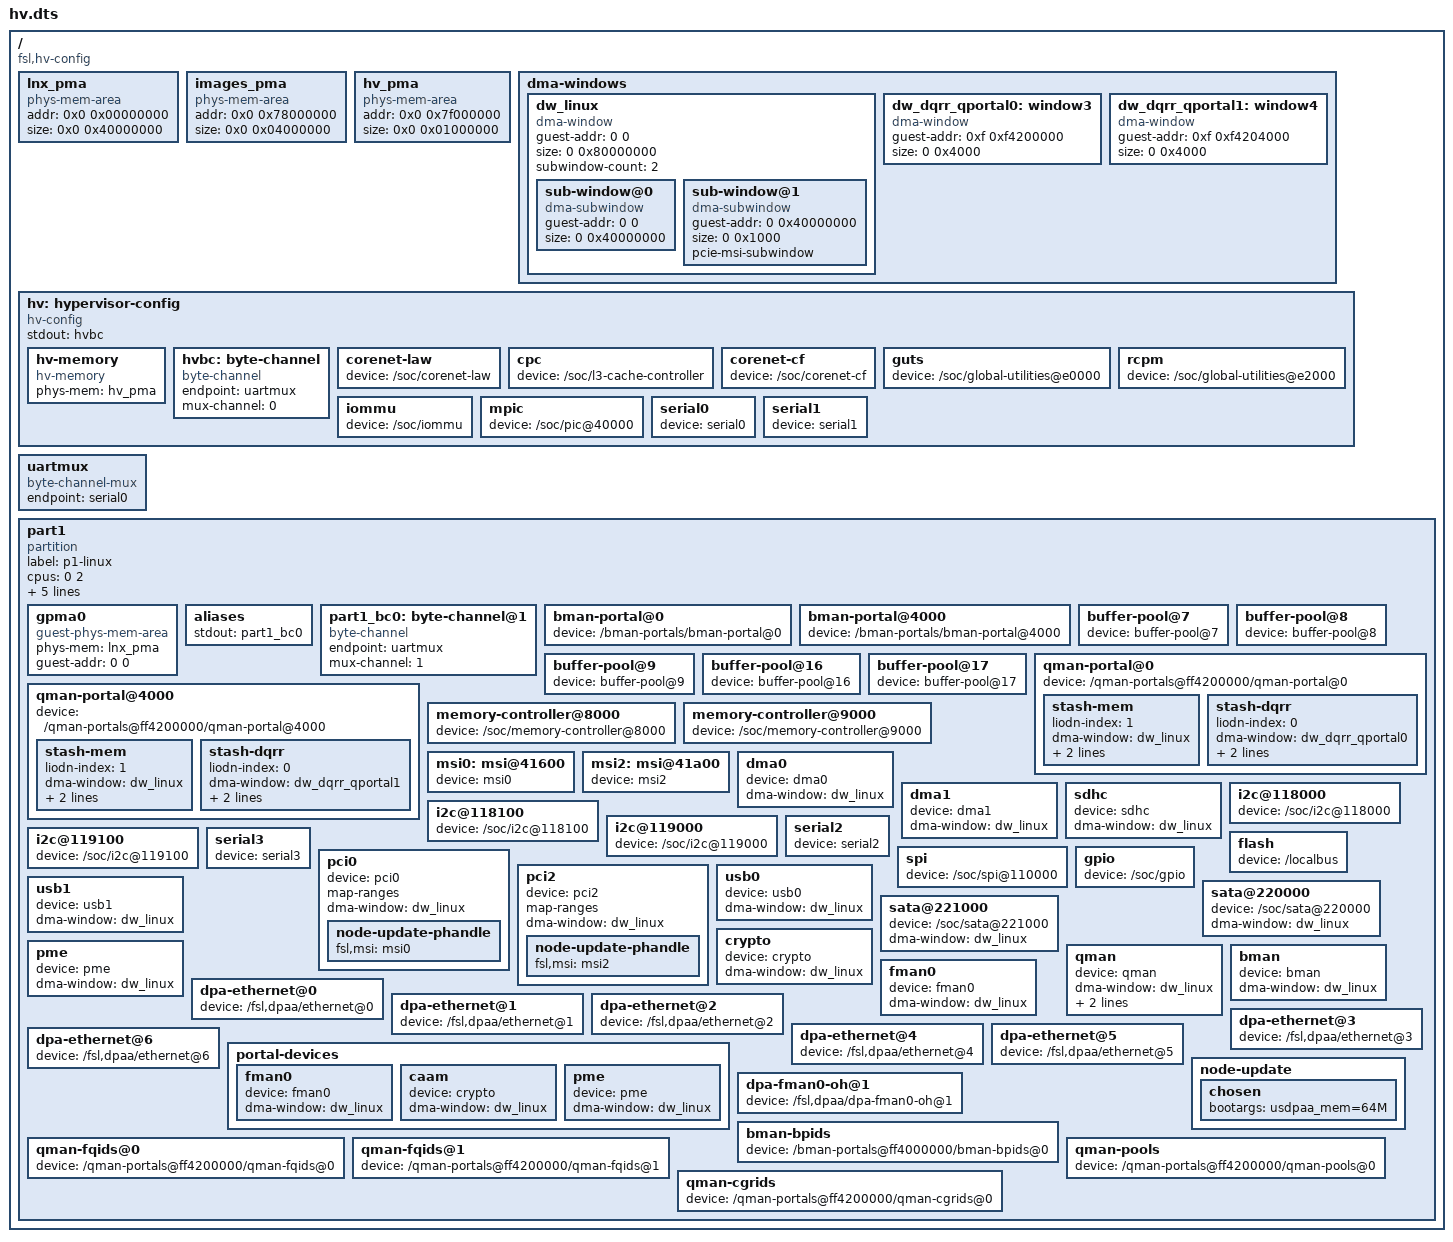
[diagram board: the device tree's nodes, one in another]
/* Hypervisor Configuration tree containing all hypervisor configuration
 * parameters and partition definition information.
 * (Note -- Please refer to Hypervisor SW Reference Manual
 * (Chapter 5 Configuration) for further details)
 *
 * Copyright 2011 Freescale Semiconductor, Inc.
 */

/dts-v1/;

/ {	// root node

	// The root node of the configuration device tree must contain a
	// compatible property that identifies the device tree as a hypervisor

	compatible = "fsl,hv-config";

	// =====================================================
	// Physical Memory Areas
	// =====================================================
	lnx_pma: lnx_pma {
		compatible = "phys-mem-area";
		addr = <0x0 0x00000000>;	// Linux
		size = <0x0 0x40000000>;	// 1GB
	};

	images_pma: images_pma {
		compatible = "phys-mem-area";
		addr = <0x0 0x78000000>;	// Used for boot-from-RAM
 		size = <0x0 0x04000000>;	// 64MB
 	};

	hv_pma: hv_pma {
		compatible = "phys-mem-area";
		addr = <0x0 0x7f000000>;	// Hypervisor
		size = <0x0 0x01000000>;	// 16MB
	};

	// =====================================================
	// DMA Windows
	// =====================================================
	dma-windows {
		// DMA window for part1_linux
		dw_linux: dw_linux {
			compatible = "dma-window";
			guest-addr = <0 0>;
			size = <0 0x80000000>; //2GB
			subwindow-count = <2>;
			sub-window@0 {
				compatible = "dma-subwindow";
				guest-addr = <0 0>;
				size = <0 0x40000000>; // 1GB
			};
			sub-window@1 {		// MSI sub-window
				compatible = "dma-subwindow";
				guest-addr = <0 0x40000000>;
				size = <0 0x1000>; // 4KB
				pcie-msi-subwindow;
			};

		};

		// DMA window for stash_dqrr for qman-portal0
		dw_dqrr_qportal0: window3 {
			compatible = "dma-window";
			guest-addr = <0xf 0xf4200000>;
			size = <0 0x4000>;
		};

		// DMA window for stash_dqrr for qman-portal1
		dw_dqrr_qportal1: window4 {
			compatible = "dma-window";
			guest-addr = <0xf 0xf4204000>;
			size = <0 0x4000>;
		};
	};

	// =====================================================
	// Hypervisor Config
	// Hypervisor is also configured via the Hypervisor
	// configuration tree. A special node and subtree defines
	// set of global configuration parameters and a number of
	// device nodes assigning I/O devices to the hypervisor
	// =====================================================
	hv: hypervisor-config {
		compatible = "hv-config";

		// phandle to byte-channel used for hypervisor's console
		stdout = <&hvbc>;

		hv-memory {
			compatible = "hv-memory";
			phys-mem = <&hv_pma>;
		};

		hvbc: byte-channel {
			compatible = "byte-channel";
			endpoint = <&uartmux>;
			mux-channel = <0>;
		};

		// Device nodes given below are the physical I/O
		// devices assigned to hypervisor
		corenet-law {
			device = "/soc/corenet-law";
		};

		cpc {
			device = "/soc/l3-cache-controller";
		};

		corenet-cf {
			device = "/soc/corenet-cf";
		};

		guts {
			device = "/soc/global-utilities@e0000";
		};

		rcpm {
			device = "/soc/global-utilities@e2000";
		};

		iommu {
			device = "/soc/iommu";
		};

		mpic {
			device = "/soc/pic@40000";
		};

		serial0: serial0 {
			device = "serial0";
		};

		serial1: serial1 {
			device = "serial1";
		};
	};

	// =====================================================
	// UART mux
	// This node is referenced by byte-channels that use mux
	// as an endpoint
	// =====================================================
	uartmux: uartmux {
		compatible = "byte-channel-mux";
		endpoint = <&serial0>;
	};

	// =====================================================
	// To keep the scenarios hv-1/2/4p as diff-able as possible
	// we always use labels part1, part2, part<n>
	// In hv-2p scenario, there are 2 partitions - 2 Linux
	// Partition1 --- part1 --- Linux partition
	// Partition2 --- part2 --- Linux partition
	// =====================================================

	// =====================================================
	// Partition 1
	// =====================================================
	part1 {
		 // Indicates that it is a partition node
		compatible = "partition";
		label = "p1-linux";

		// All CPUs #0 to #1 are assigned to this partition
		cpus = <0 2>;
		guest-image = <0xf 0xe8020000 0 0 0 0x700000>;
		linux-rootfs = <0xf 0xe9300000 0 0x01300000 0 0x02800000>;
		dtb-window = <0 0x1000000 0 0x20000>;

		// Temporary until Linux uses enable LIODN hcall
		no-dma-disable;

		gpma0 {
			compatible = "guest-phys-mem-area";
			phys-mem = <&lnx_pma>;
			guest-addr = <0 0>;
		};

		aliases {
			stdout = <&part1_bc0>;
		};

		// =====================================================
		// Devices assigned to the partition - device nodes
		// device node is child of partition node and is used to
		// assign physical I/O devices to partition
		// =====================================================
		part1_bc0: byte-channel@1 {
			compatible = "byte-channel";
			endpoint = <&uartmux>;
			mux-channel = <1>;
		};

		// Bman portals assigned to this partition
		bman-portal@0 {
			device = "/bman-portals/bman-portal@0";
		};

		bman-portal@4000 {
			device = "/bman-portals/bman-portal@4000";
		};

		// Bman buffer pools assigned to this partition
		buffer-pool@7 {
			device = "buffer-pool@7";
		};

		buffer-pool@8 {
			device = "buffer-pool@8";
		};

		buffer-pool@9 {
			device = "buffer-pool@9";
		};

		buffer-pool@16 {
			device = "buffer-pool@16";
		};

		buffer-pool@17 {
			device = "buffer-pool@17";
		};

		qman-portal@0 {
			device = "/qman-portals@ff4200000/qman-portal@0";

			stash-mem {
				liodn-index = <1>;
				dma-window = <&dw_linux>;
				operation-mapping = <0>;
				stash-dest = <3>;
			};

			stash-dqrr {
				liodn-index = <0>;
				dma-window = <&dw_dqrr_qportal0>;
				operation-mapping = <0>;
				stash-dest = <3>;
			};
		};

		qman-portal@4000 {
			device = "/qman-portals@ff4200000/qman-portal@4000";

			stash-mem {
				liodn-index = <1>;
				dma-window = <&dw_linux>;
				operation-mapping = <0>;
				stash-dest = <3>;
			};

			stash-dqrr {
				liodn-index = <0>;
				dma-window = <&dw_dqrr_qportal1>;
				operation-mapping = <0>;
				stash-dest = <3>;
			};
		};

		memory-controller@8000 {
			device = "/soc/memory-controller@8000";
		};

		memory-controller@9000 {
			device = "/soc/memory-controller@9000";
		};

		msi0: msi@41600 {
			device = "msi0";
		};

		msi2: msi@41a00 {
			device = "msi2";
		};

		dma0 {
			device = "dma0";
			dma-window = <&dw_linux>;
		};

		dma1 {
			device = "dma1";
			dma-window = <&dw_linux>;
		};

		sdhc {
			device = "sdhc";
			dma-window = <&dw_linux>;
		};

		i2c@118000 {
			device = "/soc/i2c@118000";
		};

		i2c@118100 {
			device = "/soc/i2c@118100";
		};

		i2c@119000 {
			device = "/soc/i2c@119000";
		};

		i2c@119100 {
			device = "/soc/i2c@119100";
		};

		serial2 {
			device = "serial2";
		};

		serial3 {
			device = "serial3";
		};

		flash {
			device = "/localbus";
		};

		spi {
			device = "/soc/spi@110000";
		};

		gpio {
			device = "/soc/gpio";
		};

		pci0 {
			device = "pci0";
			map-ranges;
			dma-window = <&dw_linux>;
			node-update-phandle {
				fsl,msi = <&msi0>;
			};
		};

		pci2 {
			device = "pci2";
			map-ranges;
			dma-window = <&dw_linux>;
			node-update-phandle {
				fsl,msi = <&msi2>;
			};
		};

		usb0 {
			device = "usb0";
			dma-window = <&dw_linux>;
		};

		usb1 {
			device = "usb1";
			dma-window = <&dw_linux>;
		};

		sata@220000 {
			device = "/soc/sata@220000";
			dma-window = <&dw_linux>;
		};

		sata@221000 {
			device = "/soc/sata@221000";
			dma-window = <&dw_linux>;
		};

		crypto {
			device = "crypto";
			dma-window = <&dw_linux>;
		};

		pme {
			device = "pme";
			dma-window = <&dw_linux>;
		};

		qman {
			device = "qman";
			dma-window = <&dw_linux>;
			operation-mapping = <2>;	// OMI_QMAN_PRIV
			stash-dest = <3>;		// L3/CPC
		};

		bman {
			device = "bman";
			dma-window = <&dw_linux>;
		};

		fman0 {
			device = "fman0";
			dma-window = <&dw_linux>;
		};

		// FMAN0 eth0 -- ethernet 0 assigned to this partition
		dpa-ethernet@0 {
			device = "/fsl,dpaa/ethernet@0";
		};

		// FMAN0 eth1 -- ethernet 1 assigned to this partition
		dpa-ethernet@1 {
			device = "/fsl,dpaa/ethernet@1";
		};

		// FMAN0 eth2 -- ethernet 2 assigned to this partition
		dpa-ethernet@2 {
			device = "/fsl,dpaa/ethernet@2";
		};

		// FMAN0 eth3 -- ethernet 3 assigned to this partition
		dpa-ethernet@3 {
			device = "/fsl,dpaa/ethernet@3";
		};

		// FMAN0 eth4 -- ethernet 4 assigned to this partition
		dpa-ethernet@4 {
			device = "/fsl,dpaa/ethernet@4";
		};

		// FMAN0 eth5 -- ethernet 5 assigned to this partition
		dpa-ethernet@5 {
			device = "/fsl,dpaa/ethernet@5";
		};

		// MAC-less b/w kernel and USDPAA -- assigned to this partition
		dpa-ethernet@6 {
			device = "/fsl,dpaa/ethernet@6";
		};

		portal-devices {
			fman0 {
				device = "fman0";
				dma-window = <&dw_linux>;
			};

			caam {
				device = "crypto";
				dma-window = <&dw_linux>;
			};

			pme {
				device = "pme";
				dma-window = <&dw_linux>;
			};
		};

		node-update {
			chosen {
				bootargs = "usdpaa_mem=64M";
			};
		};

		dpa-fman0-oh@1 {
			device = "/fsl,dpaa/dpa-fman0-oh@1";
		};

		bman-bpids {
			device = "/bman-portals@ff4000000/bman-bpids@0";
		};

		qman-fqids@0 {
			device = "/qman-portals@ff4200000/qman-fqids@0";
		};

		qman-fqids@1 {
			device = "/qman-portals@ff4200000/qman-fqids@1";
		};

		qman-pools {
			device = "/qman-portals@ff4200000/qman-pools@0";
		};

		qman-cgrids {
			device = "/qman-portals@ff4200000/qman-cgrids@0";
		};
	};
};
